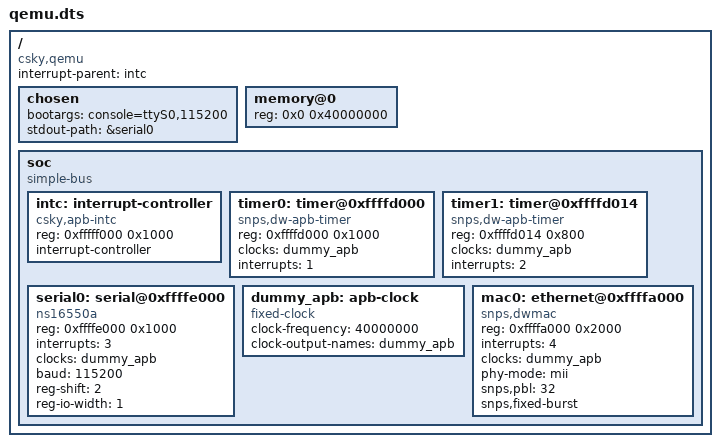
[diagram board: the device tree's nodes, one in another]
/dts-v1/;
/ {
	compatible = "csky,qemu";
	#address-cells = <1>;
	#size-cells = <1>;
	interrupt-parent = <&intc>;

	chosen {
		bootargs = "console=ttyS0,115200";
		stdout-path = &serial0;
	};

	memory@0 {
		device_type = "memory";
		reg = <0x0 0x40000000>;
	};

	soc {
		#address-cells = <1>;
		#size-cells = <1>;
		compatible = "simple-bus";
		ranges;

		intc: interrupt-controller {
			compatible = "csky,apb-intc";
			reg = <0xfffff000 0x1000>;
			interrupt-controller;
			#interrupt-cells = <1>;
		};

		timer0: timer@0xffffd000 {
			compatible = "snps,dw-apb-timer";
			reg = <0xffffd000 0x1000>;
			clocks = <&dummy_apb>;
			clock-names = "timer";
			interrupts = <1>;
		};

		timer1: timer@0xffffd014 {
			compatible = "snps,dw-apb-timer";
			reg = <0xffffd014 0x800>;
			clocks = <&dummy_apb>;
			clock-names = "timer";
			interrupts = <2>;
		};

		serial0:serial@0xffffe000 {
			compatible = "ns16550a";
			reg = <0xffffe000 0x1000>;
			interrupts = <3>;
			clocks = <&dummy_apb>;
			baud = <115200>;
			reg-shift = <2>;
			reg-io-width = <1>;
		};

		dummy_apb: apb-clock {
			compatible = "fixed-clock";
			clock-frequency = <40000000>;
			clock-output-names = "dummy_apb";
			#clock-cells = <0>;
		};

		mac0: ethernet@0xffffa000 {
			compatible = "snps,dwmac";
			reg = <0xffffa000 0x2000>;
			interrupts = <4>;
			interrupt-names = "macirq";
			clocks = <&dummy_apb>;
			clock-names = "stmmaceth";
			phy-mode = "mii";
			snps,pbl = <32>;
			snps,fixed-burst;
		};
	};

};
